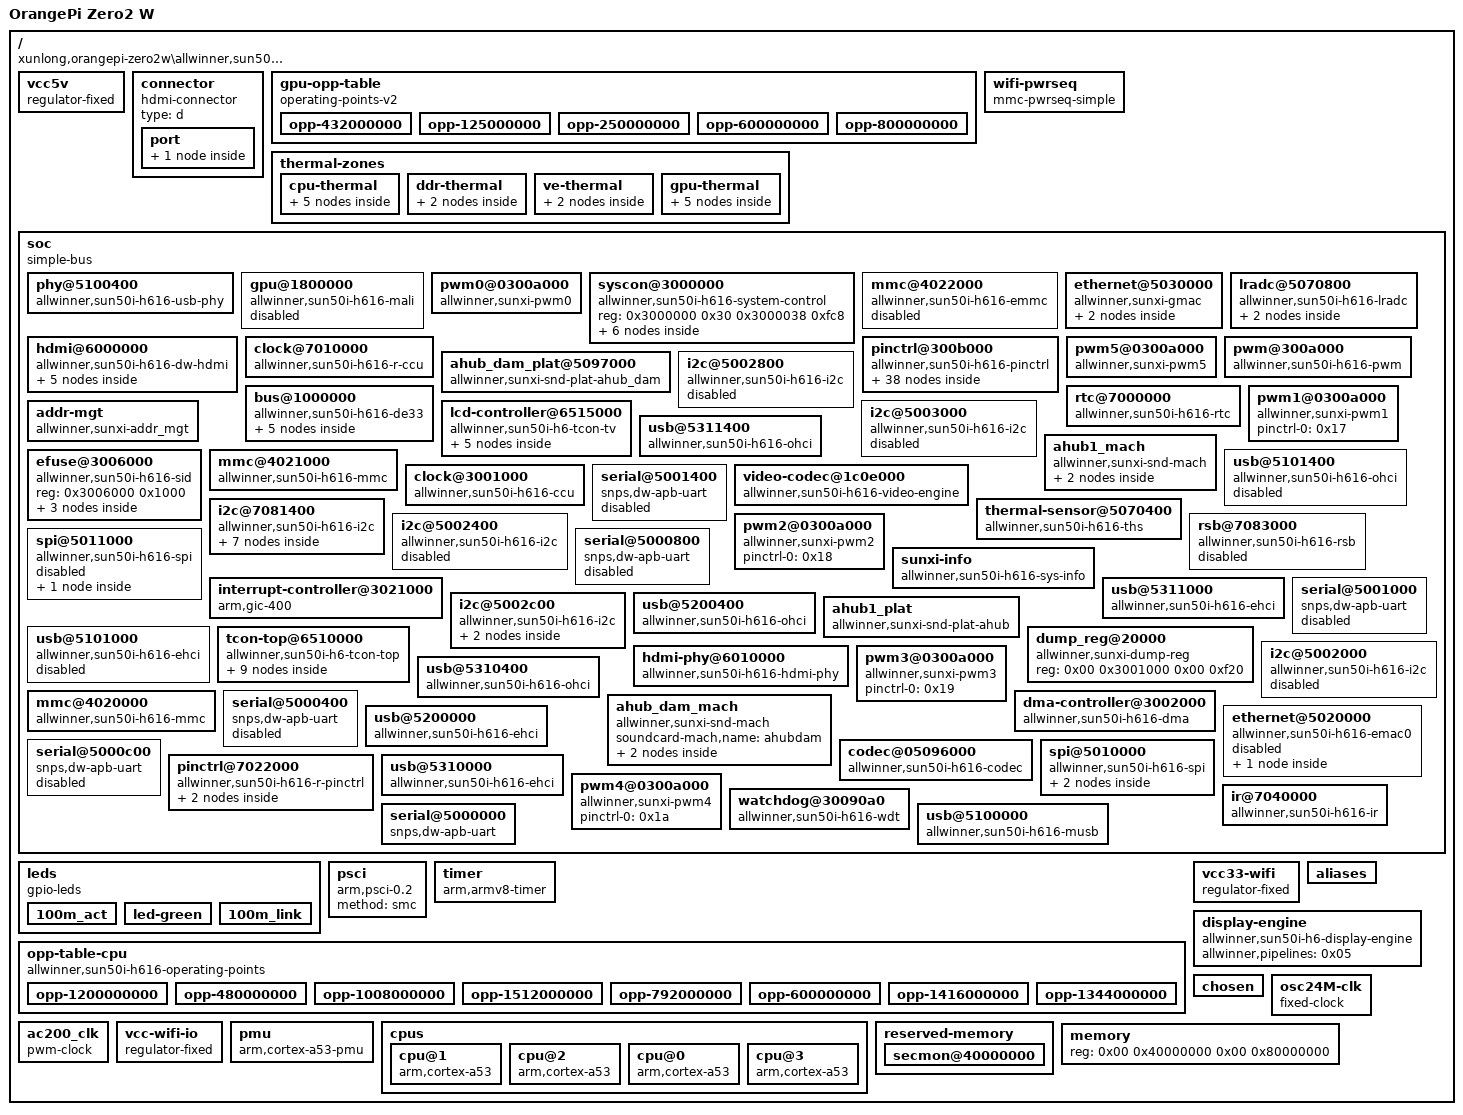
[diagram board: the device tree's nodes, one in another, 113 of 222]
/dts-v1/;

/ {
	#address-cells = <0x02>;
	model = "OrangePi Zero2 W";
	serial-number = "33802000c46ac590";
	#size-cells = <0x02>;
	interrupt-parent = <0x01>;
	compatible = "xunlong,orangepi-zero2w\allwinner,sun50i-h616\allwinner,sun50i-h618";

	vcc5v {
		regulator-max-microvolt = <0x4c4b40>;
		regulator-always-on;
		regulator-min-microvolt = <0x4c4b40>;
		regulator-name = "vcc-5v";
		compatible = "regulator-fixed";
		phandle = <0x52>;
	};

	connector {
		type = "d";
		compatible = "hdmi-connector";

		port {

			endpoint {
				remote-endpoint = <0x51>;
				phandle = <0x3f>;
			};
		};
	};

	gpu-opp-table {
		compatible = "operating-points-v2";
		phandle = <0xa2>;

		opp-432000000 {
			opp-microvolt = <0xc5c10>;
			opp-hz = <0x00 0x19bfcc00>;
		};

		opp-125000000 {
			opp-microvolt = <0xc5c10>;
			opp-hz = <0x00 0x7735940>;
		};

		opp-250000000 {
			opp-microvolt = <0xc5c10>;
			opp-hz = <0x00 0xee6b280>;
		};

		opp-600000000 {
			opp-microvolt = <0xea600>;
			opp-hz = <0x00 0x23c34600>;
		};

		opp-800000000 {
			opp-microvolt = <0x107ac0>;
			opp-hz = <0x00 0x2faf0800>;
		};
	};

	wifi-pwrseq {
		clock-names = "osc32k-out";
		clocks = <0x10 0x01>;
		reset-gpios = <0x1e 0x06 0x12 0x01>;
		compatible = "mmc-pwrseq-simple";
		post-power-on-delay-ms = <0xc8>;
		phandle = <0x22>;
	};

	thermal-zones {

		cpu-thermal {
			polling-delay = <0x00>;
			polling-delay-passive = <0x00>;
			thermal-sensors = <0x4c 0x02>;

			trips {

				cpu-crit {
					temperature = <0x186a0>;
					hysteresis = <0x00>;
					type = "critical";
				};

				cpu-alert {
					temperature = <0x14c08>;
					hysteresis = <0x7d0>;
					type = "passive";
					phandle = <0x4d>;
				};
			};

			cooling-maps {

				map0 {
					trip = <0x4d>;
					cooling-device = <0x06 0xffffffff 0xffffffff 0x07 0xffffffff 0xffffffff 0x08 0xffffffff 0xffffffff 0x09 0xffffffff 0xffffffff>;
				};
			};
		};

		ddr-thermal {
			polling-delay = <0x00>;
			polling-delay-passive = <0x00>;
			thermal-sensors = <0x4c 0x03>;

			trips {

				ddr-alert {
					temperature = <0x14c08>;
					hysteresis = <0x7d0>;
					type = "passive";
					phandle = <0xa1>;
				};
			};
		};

		ve-thermal {
			polling-delay = <0x00>;
			polling-delay-passive = <0x00>;
			thermal-sensors = <0x4c 0x01>;

			trips {

				ve-alert {
					temperature = <0x14c08>;
					hysteresis = <0x7d0>;
					type = "passive";
					phandle = <0xa0>;
				};
			};
		};

		gpu-thermal {
			polling-delay = <0x00>;
			polling-delay-passive = <0x00>;
			thermal-sensors = <0x4c 0x00>;

			trips {

				gpu-alert {
					temperature = <0x14c08>;
					hysteresis = <0x7d0>;
					type = "passive";
					phandle = <0x4e>;
				};

				gpu-crit {
					temperature = <0x186a0>;
					hysteresis = <0x00>;
					type = "critical";
				};
			};

			cooling-maps {

				map0 {
					trip = <0x4e>;
					cooling-device = <0x4f 0xffffffff 0xffffffff>;
				};
			};
		};
	};

	soc {
		#address-cells = <0x01>;
		#size-cells = <0x01>;
		compatible = "simple-bus";
		ranges = <0x00 0x00 0x00 0x40000000>;

		phy@5100400 {
			clock-names = "usb0_phy\0usb1_phy\0usb2_phy\0usb3_phy\0pmu2_clk";
			reg-names = "phy_ctrl\0pmu0\0pmu1\0pmu2\0pmu3";
			resets = <0x02 0x26 0x02 0x27 0x02 0x28 0x02 0x29>;
			clocks = <0x02 0x61 0x02 0x63 0x02 0x65 0x02 0x67 0x02 0x6e>;
			#phy-cells = <0x01>;
			compatible = "allwinner,sun50i-h616-usb-phy";
			status = "okay";
			reg = <0x5100400 0x24 0x5101800 0x14 0x5200800 0x14 0x5310800 0x14 0x5311800 0x14>;
			phandle = <0x3c>;
			reset-names = "usb0_reset\0usb1_reset\0usb2_reset\0usb3_reset";
		};

		gpu@1800000 {
			mali-supply = <0x0d>;
			clock-names = "core\0bus";
			resets = <0x02 0x03>;
			interrupts = <0x00 0x5f 0x04 0x00 0x60 0x04 0x00 0x61 0x04>;
			clocks = <0x02 0x23 0x02 0x24>;
			compatible = "allwinner,sun50i-h616-mali\0arm,mali-bifrost";
			status = "disabled";
			interrupt-names = "job\0mmu\0gpu";
			reg = <0x1800000 0x40000>;
			phandle = <0x4f>;
		};

		pwm0@0300a000 {
			compatible = "allwinner,sunxi-pwm0";
			phandle = <0x11>;
		};

		syscon@3000000 {
			#address-cells = <0x01>;
			#size-cells = <0x01>;
			compatible = "allwinner,sun50i-h616-system-control";
			ranges;
			reg = <0x3000000 0x30 0x3000038 0xfc8>;
			phandle = <0x39>;

			sram@1a00000 {
				#address-cells = <0x01>;
				#size-cells = <0x01>;
				compatible = "mmio-sram";
				ranges = <0x00 0x1a00000 0x200000>;
				reg = <0x1a00000 0x200000>;
				phandle = <0x59>;

				sram-section@0 {
					compatible = "allwinner,sun50i-h616-sram-c1";
					reg = <0x00 0x200000>;
					phandle = <0x0e>;
				};
			};

			sram@100000 {
				#address-cells = <0x01>;
				#size-cells = <0x01>;
				compatible = "mmio-sram";
				ranges = <0x00 0x100000 0x18000>;
				reg = <0x100000 0x18000>;
				phandle = <0x56>;

				scpi-sram@17c00 {
					compatible = "arm,scp-shmem";
					reg = <0x17c00 0x200>;
					phandle = <0x57>;
				};
			};

			sram@28000 {
				#address-cells = <0x01>;
				#size-cells = <0x01>;
				compatible = "mmio-sram";
				ranges = <0x00 0x28000 0x30000>;
				reg = <0x28000 0x30000>;
				phandle = <0x58>;

				sram-section@0 {
					compatible = "allwinner,sun50i-h616-sram-c\0allwinner,sun50i-a64-sram-c";
					reg = <0x00 0x1e000>;
					phandle = <0x0a>;
				};
			};
		};

		mmc@4022000 {
			mmc-ddr-3_3v;
			pinctrl-names = "default";
			#address-cells = <0x01>;
			pinctrl-0 = <0x23>;
			clock-names = "ahb\0mmc";
			cap-sd-highspeed;
			resets = <0x02 0x10>;
			cap-sdio-irq;
			interrupts = <0x00 0x25 0x04>;
			clocks = <0x02 0x41 0x02 0x3e>;
			#size-cells = <0x00>;
			compatible = "allwinner,sun50i-h616-emmc\0allwinner,sun50i-a100-emmc";
			status = "disabled";
			reg = <0x4022000 0x1000>;
			phandle = <0x6c>;
			max-frequency = <0x8f0d180>;
			cap-mmc-highspeed;
			reset-names = "ahb";
		};

		ethernet@5030000 {
			rx-delay = <0x1f>;
			gmac-power1;
			pinctrl-names = "default";
			phy-supply = <0x1d>;
			phy-mode = "rmii";
			phy-rst;
			tx-delay = <0x07>;
			pinctrl-0 = <0x3a>;
			clock-names = "bus-emac1\0emac-25m";
			reg-names = "gmac1_reg\0ephy_reg";
			local-mac-address = [02 00 c4 6a c5 90];
			resets = <0x02 0x1f>;
			interrupts = <0x00 0x0f 0x04>;
			clocks = <0x02 0x53 0x02 0x51>;
			gmac-power2;
			gmac-power0;
			compatible = "allwinner,sunxi-gmac";
			status = "okay";
			interrupt-names = "gmacirq";
			reg = <0x5030000 0x10000 0x3000034 0x04>;
			phandle = <0x82>;
			allwinner,tx-delay-ps = <0x2bc>;
			phy-handle = <0x3b>;
			reset-names = "stmmaceth";
			allwinner,rx-delay-ps = <0xc1c>;

			mdio {
				#address-cells = <0x01>;
				#size-cells = <0x00>;
				compatible = "ethernet-phy-ieee802.3-c22";
				phandle = <0x83>;

				ethernet-phy@1 {
					compatible = "ethernet-phy-ieee802.3-c22";
					reg = <0x01>;
					phandle = <0x3b>;
				};
			};
		};

		lradc@5070800 {
			vref-supply = <0x4b>;
			resets = <0x02 0x3b>;
			interrupts = <0x00 0x14 0x01>;
			clocks = <0x02 0x71>;
			compatible = "allwinner,sun50i-h616-lradc";
			status = "okay";
			reg = <0x5070800 0x400>;
			phandle = <0x9f>;

			button-500 {
				label = "KEY_1";
				channel = <0x00>;
				linux,code = <0x02>;
				voltage = <0x7a120>;
			};

			button-800 {
				label = "KEY_ENTER";
				channel = <0x00>;
				linux,code = <0x1c>;
				voltage = "\0\f5";
			};
		};

		hdmi@6000000 {
			reg-io-width = <0x01>;
			phy-names = "phy";
			clock-names = "iahb\0isfr\0tmds\0cec\0hdcp\0hdcp-bus";
			resets = <0x02 0x33 0x02 0x3a>;
			interrupts = <0x00 0x3f 0x04>;
			clocks = <0x02 0x75 0x02 0x73 0x02 0x72 0x02 0x74 0x02 0x7e 0x02 0x7f>;
			#sound-dai-cells = <0x00>;
			compatible = "allwinner,sun50i-h616-dw-hdmi\0allwinner,sun50i-h6-dw-hdmi";
			status = "okay";
			phys = <0x3d>;
			reg = <0x6000000 0x10000>;
			phandle = <0x28>;
			reset-names = "ctrl\0hdcp";

			ports {
				#address-cells = <0x01>;
				#size-cells = <0x00>;

				port@0 {
					reg = <0x00>;
					phandle = <0x8d>;

					endpoint {
						remote-endpoint = <0x3e>;
						phandle = <0x43>;
					};
				};

				port@1 {
					reg = <0x01>;
					phandle = <0x8e>;

					endpoint {
						remote-endpoint = <0x3f>;
						phandle = <0x51>;
					};
				};
			};
		};

		clock@7010000 {
			#reset-cells = <0x01>;
			clock-names = "hosc\0losc\0iosc\0pll-periph";
			clocks = <0x0f 0x10 0x00 0x10 0x02 0x02 0x04>;
			#clock-cells = <0x01>;
			compatible = "allwinner,sun50i-h616-r-ccu";
			reg = <0x7010000 0x210>;
			phandle = <0x47>;
		};

		pinctrl@300b000 {
			clock-names = "apb\0hosc\0losc";
			gpio-controller;
			interrupts = <0x00 0x33 0x04 0x00 0x34 0x04 0x00 0x35 0x04 0x00 0x2b 0x04 0x00 0x36 0x04 0x00 0x37 0x04 0x00 0x38 0x04 0x00 0x39 0x04>;
			clocks = <0x02 0x1a 0x0f 0x10 0x00>;
			compatible = "allwinner,sun50i-h616-pinctrl";
			#interrupt-cells = <0x03>;
			reg = <0x300b000 0x400>;
			phandle = <0x1e>;
			#gpio-cells = <0x03>;
			interrupt-controller;

			i2c4-ph-pins {
				function = "i2c4";
				pins = "PH6\0PH7";
				phandle = <0x34>;
			};

			pwm2-ph-pin {
				function = "pwm2";
				pins = "PH2";
				phandle = <0x62>;
			};

			pwm3-ph-pin {
				function = "pwm3";
				pins = "PH0";
				phandle = <0x63>;
			};

			pwm4-ph-pin {
				function = "pwm4";
				pins = "PH1";
				phandle = <0x64>;
			};

			spi1-cs0-pin {
				function = "spi1";
				pins = "PH5";
				phandle = <0x65>;
			};

			i2c1-pi-pins {
				function = "i2c1";
				pins = "PI7\0PI8";
				phandle = <0x2f>;
			};

			rmii-pins {
				function = "emac1";
				pins = "PA0\0PA1\0PA2\0PA3\0PA4\0PA5\0PA6\0PA7\0PA8\0PA9";
				drive-strength = <0x28>;
				phandle = <0x3a>;
			};

			pwm1-pi-pin {
				function = "pwm1";
				pins = "PI11";
				phandle = <0x17>;
			};

			pwm5-pin {
				function = "pwm5";
				pins = "PA12";
				phandle = <0x1b>;
			};

			mmc2-pins {
				function = "mmc2";
				pins = "PC0\0PC1\0PC5\0PC6\0PC8\0PC9\0PC10\0PC11\0PC13\0PC14\0PC15\0PC16";
				drive-strength = <0x1e>;
				phandle = <0x23>;
				bias-pull-up;
			};

			pwm2-pi-pin {
				function = "pwm2";
				pins = "PI12";
				phandle = <0x18>;
			};

			i2c1-ph-pins {
				function = "i2c1";
				pins = "PH0\0PH1";
				phandle = <0x5d>;
			};

			pwm3-pi-pin {
				function = "pwm3";
				pins = "PI13";
				phandle = <0x19>;
			};

			uart3-pi-pins {
				function = "uart3";
				pins = "PI9\0PI10";
				phandle = <0x2b>;
			};

			uart1-ph-pins {
				function = "uart1";
				pins = "PG6\0PG7";
				phandle = <0x66>;
			};

			pwm4-pi-pin {
				function = "pwm4";
				pins = "PI14";
				phandle = <0x1a>;
			};

			spi1-cs1-pin {
				function = "spi1";
				pins = "PH9";
				phandle = <0x38>;
			};

			ir-rx-pin {
				function = "ir_rx";
				pins = "PH10";
				phandle = <0x48>;
			};

			mmc1-pins {
				function = "mmc1";
				pins = "PG0\0PG1\0PG2\0PG3\0PG4\0PG5";
				drive-strength = <0x1e>;
				phandle = <0x1f>;
				bias-pull-up;
			};

			i2c3-ph-pins {
				function = "i2c3";
				pins = "PH4\0PH5";
				phandle = <0x5f>;
			};

			i2c3-pa-pins {
				function = "i2c3";
				pins = "PA10\0PA11";
				phandle = <0x31>;
				bias-pull-up;
			};

			rgmii-pins {
				function = "emac0";
				pins = "PI0\0PI1\0PI2\0PI3\0PI4\0PI5\0PI7\0PI8\0PI9\0PI10\0PI11\0PI12\0PI13\0PI14\0PI15\0PI16";
				drive-strength = <0x28>;
				phandle = <0x5c>;
			};

			mmc0-pins {
				function = "mmc0";
				pins = "PF0\0PF1\0PF2\0PF3\0PF4\0PF5";
				drive-strength = <0x1e>;
				phandle = <0x1c>;
				bias-pull-up;
			};

			spi0-cs0-pin {
				function = "spi0";
				pins = "PC3";
				phandle = <0x36>;
			};

			i2c0-pi-pins {
				function = "i2c0";
				pins = "PI5\0PI6";
				phandle = <0x2e>;
			};

			uart5-ph-pins {
				function = "uart5";
				pins = "PH2\0PH3";
				phandle = <0x2d>;
			};

			spi1-pins {
				function = "spi1";
				pins = "PH6\0PH7\0PH8";
				phandle = <0x37>;
			};

			i2s3-pins {
				function = "i2s3";
				pins = "PH5\0PH6\0PH7\0PH8\0PH9";
				phandle = <0x60>;
			};

			uart2-ph-rts-cts-pins {
				function = "uart2";
				pins = "PH7\0PH8";
				phandle = <0x69>;
			};

			i2c2-pi-pins {
				function = "i2c2";
				pins = "PI9\0PI10";
				phandle = <0x30>;
			};

			uart2-pi-pins {
				function = "uart2";
				pins = "PI5\0PI6";
				phandle = <0x2a>;
			};

			uart0-ph-pins {
				function = "uart0";
				pins = "PH0\0PH1";
				phandle = <0x29>;
			};

			spi0-pins {
				function = "spi0";
				pins = "PC0\0PC2\0PC4";
				phandle = <0x35>;
			};

			uart1-ph-rts-cts-pins {
				function = "uart1";
				pins = "PG8\0PG9";
				phandle = <0x67>;
			};

			i2c2-ph-pins {
				function = "i2c2";
				pins = "PH2\0PH3";
				phandle = <0x5e>;
			};

			uart4-pi-pins {
				function = "uart4";
				pins = "PI13\0PI14";
				phandle = <0x2c>;
			};

			uart2-ph-pins {
				function = "uart2";
				pins = "PH5\0PH6";
				phandle = <0x68>;
			};

			pwm1-ph-pin {
				function = "pwm1";
				pins = "PH3";
				phandle = <0x61>;
			};
		};

		pwm5@0300a000 {
			pinctrl-names = "default";
			clk_bypass_output = <0x01>;
			pinctrl-0 = <0x1b>;
			compatible = "allwinner,sunxi-pwm5";
			status = "okay";
			phandle = <0x16>;
		};

		pwm@300a000 {
			clock-names = "mod\0bus";
			resets = <0x02 0x0a>;
			clocks = <0x0f 0x02 0x2f>;
			pwm-number = <0x06>;
			#pwm-cells = <0x03>;
			compatible = "allwinner,sun50i-h616-pwm";
			status = "okay";
			reg = <0x300a000 0x400>;
			phandle = <0x53>;
			pwm-base = <0x00>;
			sunxi-pwms = <0x11 0x12 0x13 0x14 0x15 0x16>;
		};

		ahub_dam_plat@5097000 {
			clock-names = "clk_pll_audio\0clk_pll_audio_4x\0clk_audio_hub\0clk_bus_audio_hub";
			resets = <0x02 0x25>;
			clocks = <0x02 0x5b 0x02 0x5c 0x02 0x5e 0x02 0x5f>;
			#sound-dai-cells = <0x00>;
			compatible = "allwinner,sunxi-snd-plat-ahub_dam";
			status = "okay";
			reg = <0x5097000 0x1000>;
			phandle = <0x25>;
		};

		bus@1000000 {
			#address-cells = <0x01>;
			allwinner,sram = <0x0a 0x01>;
			#size-cells = <0x01>;
			compatible = "allwinner,sun50i-h616-de33\0allwinner,sun50i-a64-de2";
			ranges = <0x00 0x1000000 0x400000>;
			reg = <0x1000000 0x400000>;

			mixer@100000 {
				clock-names = "bus\0mod";
				resets = <0x0b 0x00>;
				clocks = <0x0b 0x00 0x0b 0x06>;
				compatible = "allwinner,sun50i-h616-de33-mixer-0";
				reg = <0x100000 0x100000 0x8100 0x40 0x280000 0x20000>;
				phandle = <0x05>;

				ports {
					#address-cells = <0x01>;
					#size-cells = <0x00>;

					port@1 {
						reg = <0x01>;
						phandle = <0x55>;

						endpoint {
							remote-endpoint = <0x0c>;
							phandle = <0x40>;
						};
					};
				};
			};

			clock@8000 {
				#reset-cells = <0x01>;
				clock-names = "mod\0bus";
				resets = <0x02 0x01>;
				clocks = <0x02 0x1d 0x02 0x1e>;
				#clock-cells = <0x01>;
				compatible = "allwinner,sun50i-h616-de33-clk";
				reg = <0x8000 0x100>;
				phandle = <0x0b>;
			};
		};

		i2c@5002800 {
			pinctrl-names = "default";
			#address-cells = <0x01>;
			pinctrl-0 = <0x30>;
			resets = <0x02 0x19>;
			interrupts = <0x00 0x08 0x04>;
			clocks = <0x02 0x4a>;
			#size-cells = <0x00>;
			compatible = "allwinner,sun50i-h616-i2c\0allwinner,sun8i-v536-i2c\0allwinner,sun6i-a31-i2c";
			status = "disabled";
			reg = <0x5002800 0x400>;
			phandle = <0x79>;
		};

		rtc@7000000 {
			clock-names = "bus\0hosc\0pll-32k";
			interrupts = <0x00 0x68 0x04>;
			clocks = <0x47 0x0e 0x0f 0x02 0x80>;
			#clock-cells = <0x01>;
			compatible = "allwinner,sun50i-h616-rtc";
			reg = <0x7000000 0x400>;
			phandle = <0x10>;
		};

		pwm1@0300a000 {
			pinctrl-names = "default";
			pinctrl-0 = <0x17>;
			compatible = "allwinner,sunxi-pwm1";
			phandle = <0x12>;
		};

		addr-mgt {
			compatible = "allwinner,sunxi-addr_mgt";
			status = "okay";
			type_addr_eth = <0x02>;
			type_addr_wifi = <0x02>;
			phandle = <0x9e>;
			type_addr_bt = <0x02>;
		};

		lcd-controller@6515000 {
			clock-names = "ahb\0tcon-ch1";
			resets = <0x02 0x36>;
			interrupts = <0x00 0x42 0x04>;
			clocks = <0x02 0x79 0x44 0x00>;
			compatible = "allwinner,sun50i-h6-tcon-tv\0allwinner,sun8i-r40-tcon-tv";
			reg = <0x6515000 0x1000>;
			phandle = <0x93>;
			reset-names = "lcd";

			ports {
				#address-cells = <0x01>;
				#size-cells = <0x00>;

				port@0 {
					reg = <0x00>;
					phandle = <0x94>;

					endpoint {
						remote-endpoint = <0x45>;
						phandle = <0x41>;
					};
				};

				port@1 {
					#address-cells = <0x01>;
					#size-cells = <0x00>;
					reg = <0x01>;
					phandle = <0x95>;

					endpoint@1 {
						remote-endpoint = <0x46>;
						reg = <0x01>;
						phandle = <0x42>;
					};
				};
			};
		};

		i2c@5003000 {
			pinctrl-names = "default";
			#address-cells = <0x01>;
			pinctrl-0 = <0x34>;
			resets = <0x02 0x1b>;
			interrupts = <0x00 0x0a 0x04>;
			clocks = <0x02 0x4c>;
			#size-cells = <0x00>;
			compatible = "allwinner,sun50i-h616-i2c\0allwinner,sun8i-v536-i2c\0allwinner,sun6i-a31-i2c";
			status = "disabled";
			reg = <0x5003000 0x400>;
			phandle = <0x7d>;
		};

		usb@5311400 {
			phy-names = "usb";
			resets = <0x02 0x2d 0x02 0x28>;
			interrupts = <0x00 0x21 0x04>;
			clocks = <0x02 0x6b 0x02 0x66 0x02 0x65>;
			compatible = "allwinner,sun50i-h616-ohci\0generic-ohci";
			status = "okay";
			phys = <0x3c 0x03>;
			reg = <0x5311400 0x100>;
			phandle = <0x8c>;
		};

		ahub1_mach {
			soundcard-mach,slot-num = <0x02>;
			soundcard-mach,slot-width = <0x20>;
			compatible = "allwinner,sunxi-snd-mach";
			status = "okay";
			soundcard-mach,frame-master = <0x26>;
			phandle = <0x6f>;
			soundcard-mach,name = "ahubhdmi";
			soundcard-mach,format = "i2s";
			soundcard-mach,bitclock-master = <0x26>;

			soundcard-mach,codec {
				phandle = <0x70>;
				sound-dai = <0x28>;
			};

			soundcard-mach,cpu {
				soundcard-mach,mclk-fs = <0x00>;
				soundcard-mach,pll-fs = <0x04>;
				phandle = <0x26>;
				sound-dai = <0x27>;
			};
		};

		efuse@3006000 {
			#address-cells = <0x01>;
			#size-cells = <0x01>;
			compatible = "allwinner,sun50i-h616-sid";
			reg = <0x3006000 0x1000>;
			phandle = <0x5a>;

			thermal-sensor-calibration@14 {
				reg = <0x14 0x08>;
				phandle = <0x4a>;
			};

			cpu-speed-grade@00 {
				reg = <0x00 0x02>;
				phandle = <0x50>;
			};

			ephy-calibration@2c {
				reg = <0x2c 0x02>;
				phandle = <0x33>;
			};
		};

		mmc@4021000 {
			mmc-ddr-3_3v;
			pinctrl-names = "default";
			#address-cells = <0x01>;
			pinctrl-0 = <0x1f>;
			clock-names = "ahb\0mmc";
			cap-sd-highspeed;
			vqmmc-supply = <0x21>;
			bus-width = <0x04>;
			non-removable;
			resets = <0x02 0x0f>;
			cap-sdio-irq;
			interrupts = <0x00 0x24 0x04>;
			clocks = <0x02 0x40 0x02 0x3d>;
			#size-cells = <0x00>;
			vmmc-supply = <0x20>;
			mmc-ddr-1_8v;
			compatible = "allwinner,sun50i-h616-mmc\0allwinner,sun50i-a100-mmc";
			status = "okay";
			mmc-pwrseq = <0x22>;
			reg = <0x4021000 0x1000>;
			phandle = <0x6b>;
			max-frequency = <0x8f0d180>;
			cap-mmc-highspeed;
			reset-names = "ahb";
		};

		usb@5101400 {
			phy-names = "usb";
			resets = <0x02 0x2a 0x02 0x28>;
			interrupts = <0x00 0x1b 0x04>;
			clocks = <0x02 0x68 0x02 0x60 0x02 0x65>;
			compatible = "allwinner,sun50i-h616-ohci\0generic-ohci";
			status = "disabled";
			phys = <0x3c 0x00>;
			reg = <0x5101400 0x100>;
			phandle = <0x86>;
		};

		clock@3001000 {
			#reset-cells = <0x01>;
			clock-names = "hosc\0losc\0iosc";
			clocks = <0x0f 0x10 0x00 0x10 0x02>;
			#clock-cells = <0x01>;
			compatible = "allwinner,sun50i-h616-ccu";
			reg = <0x3001000 0x1000>;
			phandle = <0x02>;
		};

		serial@5001400 {
			reg-io-width = <0x04>;
			pinctrl-names = "default";
			pinctrl-0 = <0x2d>;
			resets = <0x02 0x16>;
			interrupts = <0x00 0x05 0x04>;
			clocks = <0x02 0x47>;
			compatible = "snps,dw-apb-uart";
			status = "disabled";
			reg = <0x5001400 0x400>;
			phandle = <0x76>;
			reg-shift = <0x02>;
		};

		video-codec@1c0e000 {
			clock-names = "ahb\0mod\0ram";
			allwinner,sram = <0x0e 0x01>;
			resets = <0x02 0x05>;
			interrupts = <0x00 0x5d 0x04>;
			clocks = <0x02 0x29 0x02 0x28 0x02 0x33>;
			compatible = "allwinner,sun50i-h616-video-engine";
			reg = <0x1c0e000 0x2000>;
		};

		thermal-sensor@5070400 {
			nvmem-cells = <0x4a>;
			clock-names = "bus";
			resets = <0x02 0x21>;
			interrupts = <0x00 0x13 0x04>;
			clocks = <0x02 0x56>;
			#thermal-sensor-cells = <0x01>;
			compatible = "allwinner,sun50i-h616-ths";
			nvmem-cell-names = "calibration";
			reg = <0x5070400 0x400>;
			phandle = <0x4c>;
		};

		i2c@7081400 {
			#address-cells = <0x01>;
			resets = <0x47 0x04>;
			interrupts = <0x00 0x69 0x04>;
			clocks = <0x47 0x08>;
			#size-cells = <0x00>;
			compatible = "allwinner,sun50i-h616-i2c\0allwinner,sun8i-v536-i2c\0allwinner,sun6i-a31-i2c";
			status = "okay";
			reg = <0x7081400 0x400>;
			phandle = <0x99>;

			pmic@36 {
				wakeup-source;
				interrupts = <0x02 0x09 0x08>;
				interrupt-parent = <0x1e>;
				compatible = "x-powers,axp313a";
				#interrupt-cells = <0x01>;
				reg = <0x36>;
				phandle = <0x9a>;
				interrupt-controller;

				regulators {

					dcdc3 {
						regulator-max-microvolt = <0x10c8e0>;
						regulator-step-delay-us = <0x19>;
						regulator-always-on;
						regulator-min-microvolt = <0x10c8e0>;
						regulator-name = "axp313a-dcdc3";
						regulator-final-delay-us = <0x32>;
						phandle = <0x9b>;
					};

					dcdc1 {
						regulator-max-microvolt = <0x10c8e0>;
						regulator-step-delay-us = <0x19>;
						regulator-always-on;
						regulator-min-microvolt = <0x7a120>;
						regulator-name = "axp313a-dcdc1";
						regulator-final-delay-us = <0x32>;
						phandle = <0x0d>;
					};

					ldo2 {
						regulator-max-microvolt = <0x325aa0>;
						regulator-step-delay-us = <0x19>;
						regulator-always-on;
						regulator-min-microvolt = <0x325aa0>;
						regulator-name = "axp313a-dldo1";
						regulator-final-delay-us = <0x32>;
						phandle = <0x1d>;
					};

					dcdc2 {
						regulator-max-microvolt = <0x124f80>;
						regulator-step-delay-us = <0x19>;
						regulator-always-on;
						regulator-min-microvolt = <0x7a120>;
						regulator-name = "axp313a-dcdc2";
						regulator-ramp-delay = <0xc8>;
						regulator-final-delay-us = <0x32>;
						phandle = <0x04>;
					};

					ldo1 {
						regulator-max-microvolt = <0x1b7740>;
						regulator-step-delay-us = <0x19>;
						regulator-always-on;
						regulator-min-microvolt = <0x1b7740>;
						regulator-name = "axp313a-aldo1";
						regulator-final-delay-us = <0x32>;
						phandle = <0x4b>;
					};
				};
			};
		};

		i2c@5002400 {
			pinctrl-names = "default";
			#address-cells = <0x01>;
			pinctrl-0 = <0x2f>;
			resets = <0x02 0x18>;
			interrupts = <0x00 0x07 0x04>;
			clocks = <0x02 0x49>;
			#size-cells = <0x00>;
			compatible = "allwinner,sun50i-h616-i2c\0allwinner,sun8i-v536-i2c\0allwinner,sun6i-a31-i2c";
			status = "disabled";
			reg = <0x5002400 0x400>;
			phandle = <0x78>;
		};

		pwm2@0300a000 {
			pinctrl-names = "default";
			pinctrl-0 = <0x18>;
			compatible = "allwinner,sunxi-pwm2";
			phandle = <0x13>;
		};

		rsb@7083000 {
			pinctrl-names = "default";
			#address-cells = <0x01>;
			pinctrl-0 = <0x49>;
			resets = <0x47 0x07>;
			interrupts = <0x00 0x6d 0x04>;
			clocks = <0x47 0x0d>;
			#size-cells = <0x00>;
			clock-frequency = <0x2dc6c0>;
			compatible = "allwinner,sun50i-h616-rsb\0allwinner,sun8i-a23-rsb";
			status = "disabled";
			reg = <0x7083000 0x400>;
			phandle = <0x9c>;
		};

		sunxi-info {
			compatible = "allwinner,sun50i-h616-sys-info";
			status = "okay";
		};

		spi@5011000 {
			pinctrl-names = "default";
			#address-cells = <0x01>;
			pinctrl-0 = <0x37 0x38>;
			clock-names = "ahb\0mod";
			resets = <0x02 0x1d>;
			interrupts = <0x00 0x0d 0x04>;
			clocks = <0x02 0x50 0x02 0x4e>;
			#size-cells = <0x00>;
			dma-names = "rx\0tx";
			compatible = "allwinner,sun50i-h616-spi\0allwinner,sun8i-h3-spi";
			status = "disabled";
			reg = <0x5011000 0x1000>;
			phandle = <0x7f>;
			dmas = <0x24 0x17 0x24 0x17>;

			spidev@1 {
				spi-max-frequency = <0xf4240>;
				compatible = "rohm,dh2228fv";
				status = "disabled";
				reg = <0x01>;
			};
		};

		serial@5000800 {
			reg-io-width = <0x04>;
			pinctrl-names = "default";
			pinctrl-0 = <0x2a>;
			resets = <0x02 0x13>;
			interrupts = <0x00 0x02 0x04>;
			clocks = <0x02 0x44>;
			compatible = "snps,dw-apb-uart";
			status = "disabled";
			reg = <0x5000800 0x400>;
			phandle = <0x73>;
			reg-shift = <0x02>;
		};

		interrupt-controller@3021000 {
			interrupts = <0x01 0x09 0xf04>;
			compatible = "arm,gic-400";
			#interrupt-cells = <0x03>;
			reg = <0x3021000 0x1000 0x3022000 0x2000 0x3024000 0x2000 0x3026000 0x2000>;
			phandle = <0x01>;
			interrupt-controller;
		};

		usb@5311000 {
			phy-names = "usb";
			resets = <0x02 0x2d 0x02 0x31 0x02 0x28>;
			interrupts = <0x00 0x20 0x04>;
			clocks = <0x02 0x6b 0x02 0x6f 0x02 0x66 0x02 0x65>;
			compatible = "allwinner,sun50i-h616-ehci\0generic-ehci";
			status = "okay";
			phys = <0x3c 0x03>;
			reg = <0x5311000 0x100>;
			phandle = <0x8b>;
		};

		i2c@5002c00 {
			pinctrl-names = "default";
			#address-cells = <0x01>;
			pinctrl-0 = <0x31>;
			resets = <0x02 0x1a>;
			interrupts = <0x00 0x09 0x04>;
			clocks = <0x02 0x4b>;
			#size-cells = <0x00>;
			compatible = "allwinner,sun50i-h616-i2c\0allwinner,sun8i-v536-i2c\0allwinner,sun6i-a31-i2c";
			status = "okay";
			reg = <0x5002c00 0x400>;
			phandle = <0x7a>;

			mfd@10 {
				nvmem-cells = <0x33>;
				clocks = <0x32>;
				compatible = "x-powers,ac200";
				nvmem-cell-names = "calibration";
				reg = <0x10>;
				phandle = <0x7b>;

				phy {
					compatible = "x-powers,ac200-ephy";
					status = "okay";
					phandle = <0x7c>;
				};
			};
		};

		usb@5200400 {
			phy-names = "usb";
			resets = <0x02 0x2b 0x02 0x28>;
			interrupts = <0x00 0x1d 0x04>;
			clocks = <0x02 0x69 0x02 0x62 0x02 0x65>;
			compatible = "allwinner,sun50i-h616-ohci\0generic-ohci";
			status = "okay";
			phys = <0x3c 0x01>;
			reg = <0x5200400 0x100>;
			phandle = <0x88>;
		};

		ahub1_plat {
			capture_cma = <0x80>;
			rx_fifo_size = <0x80>;
			rx_pin = <0x00>;
			dma-names = "tx\0rx";
			#sound-dai-cells = <0x00>;
			compatible = "allwinner,sunxi-snd-plat-ahub";
			status = "okay";
			tdm_num = <0x01>;
			phandle = <0x27>;
			dmas = <0x24 0x04 0x24 0x04>;
			playback_cma = <0x80>;
			tx_fifo_size = <0x80>;
			tx_pin = <0x00>;
			apb_num = <0x01>;
		};

		usb@5101000 {
			phy-names = "usb";
			resets = <0x02 0x2a 0x02 0x2e 0x02 0x28>;
			interrupts = <0x00 0x1a 0x04>;
			clocks = <0x02 0x68 0x02 0x6c 0x02 0x60 0x02 0x65>;
			compatible = "allwinner,sun50i-h616-ehci\0generic-ehci";
			status = "disabled";
			phys = <0x3c 0x00>;
			reg = <0x5101000 0x100>;
			phandle = <0x85>;
		};

		tcon-top@6510000 {
			clock-output-names = "tcon-top-tv0";
			clock-names = "bus\0tcon-tv0";
			resets = <0x02 0x35>;
			clocks = <0x02 0x76 0x02 0x77>;
			#clock-cells = <0x01>;
			compatible = "allwinner,sun50i-h6-tcon-top";
			reg = <0x6510000 0x1000>;
			phandle = <0x44>;

			ports {
				#address-cells = <0x01>;
				#size-cells = <0x00>;

				port@0 {
					#address-cells = <0x01>;
					#size-cells = <0x00>;
					reg = <0x00>;
					phandle = <0x8f>;

					endpoint@0 {
						remote-endpoint = <0x40>;
						reg = <0x00>;
						phandle = <0x0c>;
					};
				};

				port@5 {
					reg = <0x05>;
					phandle = <0x92>;

					endpoint {
						remote-endpoint = <0x43>;
						phandle = <0x3e>;
					};
				};

				port@1 {
					#address-cells = <0x01>;
					#size-cells = <0x00>;
					reg = <0x01>;
					phandle = <0x90>;

					endpoint@2 {
						remote-endpoint = <0x41>;
						reg = <0x02>;
						phandle = <0x45>;
					};
				};

				port@4 {
					#address-cells = <0x01>;
					#size-cells = <0x00>;
					reg = <0x04>;
					phandle = <0x91>;

					endpoint@0 {
						remote-endpoint = <0x42>;
						reg = <0x00>;
						phandle = <0x46>;
					};
				};
			};
		};

		serial@5001000 {
			reg-io-width = <0x04>;
			pinctrl-names = "default";
			pinctrl-0 = <0x2c>;
			resets = <0x02 0x15>;
			interrupts = <0x00 0x04 0x04>;
			clocks = <0x02 0x46>;
			compatible = "snps,dw-apb-uart";
			status = "disabled";
			reg = <0x5001000 0x400>;
			phandle = <0x75>;
			reg-shift = <0x02>;
		};

		dump_reg@20000 {
			compatible = "allwinner,sunxi-dump-reg";
			status = "okay";
			reg = <0x00 0x3001000 0x00 0xf20>;
			phandle = <0x9d>;
		};

		hdmi-phy@6010000 {
			clock-names = "bus\0mod";
			resets = <0x02 0x34>;
			clocks = <0x02 0x75 0x02 0x73>;
			#phy-cells = <0x00>;
			compatible = "allwinner,sun50i-h616-hdmi-phy";
			reg = <0x6010000 0x10000>;
			phandle = <0x3d>;
			reset-names = "phy";
		};

		i2c@5002000 {
			pinctrl-names = "default";
			#address-cells = <0x01>;
			pinctrl-0 = <0x2e>;
			resets = <0x02 0x17>;
			interrupts = <0x00 0x06 0x04>;
			clocks = <0x02 0x48>;
			#size-cells = <0x00>;
			compatible = "allwinner,sun50i-h616-i2c\0allwinner,sun8i-v536-i2c\0allwinner,sun6i-a31-i2c";
			status = "disabled";
			reg = <0x5002000 0x400>;
			phandle = <0x77>;
		};

		pwm3@0300a000 {
			pinctrl-names = "default";
			pinctrl-0 = <0x19>;
			compatible = "allwinner,sunxi-pwm3";
			phandle = <0x14>;
		};

		usb@5310400 {
			phy-names = "usb";
			resets = <0x02 0x2c>;
			interrupts = <0x00 0x1f 0x04>;
			clocks = <0x02 0x6a 0x02 0x64>;
			compatible = "allwinner,sun50i-h616-ohci\0generic-ohci";
			status = "okay";
			phys = <0x3c 0x02>;
			reg = <0x5310400 0x100>;
			phandle = <0x8a>;
		};

		mmc@4020000 {
			mmc-ddr-3_3v;
			pinctrl-names = "default";
			#address-cells = <0x01>;
			pinctrl-0 = <0x1c>;
			clock-names = "ahb\0mmc";
			cap-sd-highspeed;
			bus-width = <0x04>;
			resets = <0x02 0x0e>;
			cap-sdio-irq;
			interrupts = <0x00 0x23 0x04>;
			clocks = <0x02 0x3f 0x02 0x3c>;
			#size-cells = <0x00>;
			vmmc-supply = <0x1d>;
			compatible = "allwinner,sun50i-h616-mmc\0allwinner,sun50i-a100-mmc";
			status = "okay";
			reg = <0x4020000 0x1000>;
			phandle = <0x6a>;
			max-frequency = <0x2faf080>;
			cap-mmc-highspeed;
			reset-names = "ahb";
			cd-gpios = <0x1e 0x05 0x06 0x01>;
		};

		serial@5000400 {
			reg-io-width = <0x04>;
			resets = <0x02 0x12>;
			interrupts = <0x00 0x01 0x04>;
			clocks = <0x02 0x43>;
			compatible = "snps,dw-apb-uart";
			status = "disabled";
			reg = <0x5000400 0x400>;
			phandle = <0x72>;
			reg-shift = <0x02>;
		};

		dma-controller@3002000 {
			clock-names = "bus\0mbus";
			resets = <0x02 0x06>;
			interrupts = <0x00 0x2a 0x04>;
			clocks = <0x02 0x2a 0x02 0x32>;
			dma-requests = <0x31>;
			compatible = "allwinner,sun50i-h616-dma";
			reg = <0x3002000 0x1000>;
			phandle = <0x24>;
			dma-channels = <0x10>;
			#dma-cells = <0x01>;
		};

		ahub_dam_mach {
			compatible = "allwinner,sunxi-snd-mach";
			status = "okay";
			phandle = <0x6e>;
			soundcard-mach,name = "ahubdam";

			soundcard-mach,codec {
			};

			soundcard-mach,cpu {
				sound-dai = <0x25>;
			};
		};

		usb@5200000 {
			phy-names = "usb";
			resets = <0x02 0x2b 0x02 0x2f 0x02 0x28>;
			interrupts = <0x00 0x1c 0x04>;
			clocks = <0x02 0x69 0x02 0x6d 0x02 0x62 0x02 0x65>;
			compatible = "allwinner,sun50i-h616-ehci\0generic-ehci";
			status = "okay";
			phys = <0x3c 0x01>;
			reg = <0x5200000 0x100>;
			phandle = <0x87>;
		};

		ethernet@5020000 {
			syscon = <0x39>;
			clock-names = "stmmaceth";
			resets = <0x02 0x1e>;
			interrupts = <0x00 0x0e 0x04>;
			clocks = <0x02 0x52>;
			compatible = "allwinner,sun50i-h616-emac0\0allwinner,sun50i-a64-emac";
			status = "disabled";
			interrupt-names = "macirq";
			reg = <0x5020000 0x10000>;
			phandle = <0x80>;
			reset-names = "stmmaceth";

			mdio {
				#address-cells = <0x01>;
				#size-cells = <0x00>;
				compatible = "snps,dwmac-mdio";
				phandle = <0x81>;
			};
		};

		codec@05096000 {
			clock-names = "apb\0audio-codec-1x\0audio-codec-4x";
			resets = <0x02 0x24>;
			interrupts = <0x00 0x3a 0x04>;
			clocks = <0x02 0x5d 0x02 0x5b 0x02 0x5c>;
			dma-names = "tx";
			#sound-dai-cells = <0x00>;
			compatible = "allwinner,sun50i-h616-codec";
			status = "okay";
			reg = <0x5096000 0x31c>;
			phandle = <0x6d>;
			dmas = <0x24 0x06>;
			allwinner,audio-routing = "Line Out\0LINEOUT";
		};

		serial@5000c00 {
			reg-io-width = <0x04>;
			pinctrl-names = "default";
			pinctrl-0 = <0x2b>;
			resets = <0x02 0x14>;
			interrupts = <0x00 0x03 0x04>;
			clocks = <0x02 0x45>;
			compatible = "snps,dw-apb-uart";
			status = "disabled";
			reg = <0x5000c00 0x400>;
			phandle = <0x74>;
			reg-shift = <0x02>;
		};

		spi@5010000 {
			pinctrl-names = "default";
			#address-cells = <0x01>;
			pinctrl-0 = <0x35 0x36>;
			clock-names = "ahb\0mod";
			resets = <0x02 0x1c>;
			interrupts = <0x00 0x0c 0x04>;
			clocks = <0x02 0x4f 0x02 0x4d>;
			#size-cells = <0x00>;
			dma-names = "rx\0tx";
			compatible = "allwinner,sun50i-h616-spi\0allwinner,sun8i-h3-spi";
			status = "okay";
			reg = <0x5010000 0x1000>;
			phandle = <0x7e>;
			dmas = <0x24 0x16 0x24 0x16>;

			spidev@0 {
				spi-max-frequency = <0xf4240>;
				compatible = "rohm,dh2228fv";
				status = "disabled";
				reg = <0x00>;
			};

			flash@0 {
				#address-cells = <0x01>;
				#size-cells = <0x01>;
				spi-max-frequency = <0x2625a00>;
				compatible = "jedec,spi-nor";
				status = "okay";
				reg = <0x00>;
			};
		};

		pinctrl@7022000 {
			clock-names = "apb\0hosc\0losc";
			gpio-controller;
			interrupts = <0x00 0x2b 0x04>;
			clocks = <0x47 0x02 0x0f 0x10 0x00>;
			compatible = "allwinner,sun50i-h616-r-pinctrl";
			#interrupt-cells = <0x03>;
			reg = <0x7022000 0x400>;
			phandle = <0x96>;
			#gpio-cells = <0x03>;
			interrupt-controller;

			r-rsb-pins {
				function = "s_rsb";
				pins = "PL0\0PL1";
				phandle = <0x49>;
			};

			r-i2c-pins {
				function = "s_i2c";
				pins = "PL0\0PL1";
				phandle = <0x97>;
			};
		};

		usb@5310000 {
			phy-names = "usb";
			resets = <0x02 0x2c 0x02 0x30>;
			interrupts = <0x00 0x1e 0x04>;
			clocks = <0x02 0x6a 0x02 0x6e 0x02 0x64>;
			compatible = "allwinner,sun50i-h616-ehci\0generic-ehci";
			status = "okay";
			phys = <0x3c 0x02>;
			reg = <0x5310000 0x100>;
			phandle = <0x89>;
		};

		pwm4@0300a000 {
			pinctrl-names = "default";
			pinctrl-0 = <0x1a>;
			compatible = "allwinner,sunxi-pwm4";
			phandle = <0x15>;
		};

		ir@7040000 {
			pinctrl-names = "default";
			pinctrl-0 = <0x48>;
			clock-names = "apb\0ir";
			resets = <0x47 0x05>;
			interrupts = <0x00 0x6a 0x04>;
			clocks = <0x47 0x09 0x47 0x0b>;
			compatible = "allwinner,sun50i-h616-ir\0allwinner,sun6i-a31-ir";
			status = "okay";
			reg = <0x7040000 0x400>;
			phandle = <0x98>;
		};

		watchdog@30090a0 {
			interrupts = <0x00 0x32 0x04>;
			clocks = <0x0f>;
			compatible = "allwinner,sun50i-h616-wdt\0allwinner,sun6i-a31-wdt";
			status = "okay";
			reg = <0x30090a0 0x20>;
			phandle = <0x5b>;
		};

		usb@5100000 {
			phy-names = "usb";
			resets = <0x02 0x32>;
			interrupts = <0x00 0x19 0x04>;
			clocks = <0x02 0x70>;
			extcon = <0x3c 0x00>;
			compatible = "allwinner,sun50i-h616-musb\0allwinner,sun8i-h3-musb";
			status = "okay";
			interrupt-names = "mc";
			phys = <0x3c 0x00>;
			reg = <0x5100000 0x400>;
			phandle = <0x84>;
			dr_mode = "peripheral";
		};

		serial@5000000 {
			reg-io-width = <0x04>;
			pinctrl-names = "default";
			pinctrl-0 = <0x29>;
			resets = <0x02 0x11>;
			interrupts = <0x00 0x00 0x04>;
			clocks = <0x02 0x42>;
			compatible = "snps,dw-apb-uart";
			status = "okay";
			reg = <0x5000000 0x400>;
			phandle = <0x71>;
			reg-shift = <0x02>;
		};
	};

	leds {
		compatible = "gpio-leds";
		phandle = <0xa3>;

		100m_act {
			label = "100m_act";
			default-state = "off";
			gpios = <0x1e 0x02 0x10 0x00>;
		};

		led-green {
			linux,default-trigger = "heartbeat";
			label = "green_led";
			gpios = <0x1e 0x02 0x0d 0x00>;
		};

		100m_link {
			label = "100m_link";
			default-state = "off";
			gpios = <0x1e 0x02 0x0f 0x00>;
		};
	};

	psci {
		method = "smc";
		compatible = "arm,psci-0.2";
	};

	timer {
		arm,no-tick-in-suspend;
		interrupts = <0x01 0x0d 0xf04 0x01 0x0e 0xf04 0x01 0x0b 0xf04 0x01 0x0a 0xf04>;
		compatible = "arm,armv8-timer";
	};

	opp-table-cpu {
		nvmem-cells = <0x50>;
		opp-shared;
		compatible = "allwinner,sun50i-h616-operating-points";
		phandle = <0x03>;

		opp-1200000000 {
			opp-microvolt-speed1 = <0x10c8e0 0x10c8e0 0x10c8e0>;
			opp-hz = <0x00 0x47868c00>;
			opp-microvolt-speed2 = <0x10c8e0 0x10c8e0 0x10c8e0>;
			opp-microvolt-speed0 = <0xea600 0xea600 0x10c8e0>;
			clock-latency-ns = <0x3b9b0>;
		};

		opp-480000000 {
			opp-microvolt-speed1 = <0xdbba0 0xdbba0 0x10c8e0>;
			opp-hz = <0x00 0x1c9c3800>;
			opp-microvolt-speed2 = <0xdbba0 0xdbba0 0x10c8e0>;
			opp-microvolt-speed0 = <0xdbba0 0xdbba0 0x10c8e0>;
			clock-latency-ns = <0x3b9b0>;
		};

		opp-1008000000 {
			opp-microvolt-speed1 = <0xf9060 0xf9060 0x10c8e0>;
			opp-hz = <0x00 0x3c14dc00>;
			opp-microvolt-speed2 = <0xf9060 0xf9060 0x10c8e0>;
			opp-microvolt-speed0 = <0xdbba0 0xdbba0 0x10c8e0>;
			clock-latency-ns = <0x3b9b0>;
		};

		opp-1512000000 {
			opp-microvolt-speed1 = <0x10c8e0 0x10c8e0 0x10c8e0>;
			opp-hz = <0x00 0x5a1f4a00>;
			opp-microvolt-speed2 = <0x10c8e0 0x10c8e0 0x10c8e0>;
			opp-microvolt-speed0 = <0x10c8e0 0x10c8e0 0x10c8e0>;
			clock-latency-ns = <0x3b9b0>;
		};

		opp-792000000 {
			opp-microvolt-speed1 = <0xe57e0 0xe57e0 0x10c8e0>;
			opp-hz = <0x00 0x2f34f600>;
			opp-microvolt-speed2 = <0xe57e0 0xe57e0 0x10c8e0>;
			opp-microvolt-speed0 = <0xdbba0 0xdbba0 0x10c8e0>;
			clock-latency-ns = <0x3b9b0>;
		};

		opp-600000000 {
			opp-microvolt-speed1 = <0xe09c0 0xe09c0 0x10c8e0>;
			opp-hz = <0x00 0x23c34600>;
			opp-microvolt-speed2 = <0xe09c0 0xe09c0 0x10c8e0>;
			opp-microvolt-speed0 = <0xdbba0 0xdbba0 0x10c8e0>;
			clock-latency-ns = <0x3b9b0>;
		};

		opp-1416000000 {
			opp-microvolt-speed1 = <0x10c8e0 0x10c8e0 0x10c8e0>;
			opp-hz = <0x00 0x54667200>;
			opp-microvolt-speed2 = <0x10c8e0 0x10c8e0 0x10c8e0>;
			opp-microvolt-speed0 = <0x10c8e0 0x10c8e0 0x10c8e0>;
			clock-latency-ns = <0x3b9b0>;
		};

		opp-1344000000 {
			opp-microvolt-speed1 = <0x10c8e0 0x10c8e0 0x10c8e0>;
			opp-hz = <0x00 0x501bd000>;
			opp-microvolt-speed2 = <0x10c8e0 0x10c8e0 0x10c8e0>;
			opp-microvolt-speed0 = <0x100590 0x100590 0x10c8e0>;
			clock-latency-ns = <0x3b9b0>;
		};
	};

	vcc33-wifi {
		regulator-max-microvolt = <0x325aa0>;
		regulator-always-on;
		regulator-min-microvolt = <0x325aa0>;
		regulator-name = "vcc33-wifi";
		compatible = "regulator-fixed";
		phandle = <0x20>;
		vin-supply = <0x52>;
	};

	aliases {
		ethernet0 = "/soc/ethernet@5030000";
		serial5 = "/soc/serial@5001400";
		serial3 = "/soc/serial@5000c00";
		serial4 = "/soc/serial@5001000";
		serial2 = "/soc/serial@5000800";
		serial0 = "/soc/serial@5000000";
	};

	display-engine {
		allwinner,pipelines = <0x05>;
		compatible = "allwinner,sun50i-h6-display-engine";
		status = "okay";
		phandle = <0x54>;
	};

	chosen {
		linux,initrd-end = <0x00 0x49fff4d9>;
		bootargs = "root=UUID=1eb12926-39f4-4c68-9f32-38360510d193 rootwait rootfstype=ext4 splash=verbose console=ttyS0,115200 console=tty1 consoleblank=0 loglevel=1 ubootpart=703fcbf5-01 usb-storage.quirks=   cgroup_enable=memory swapaccount=1";
		linux,initrd-start = <0x00 0x49430000>;
		stdout-path = "serial0:115200n8";
	};

	osc24M-clk {
		clock-output-names = "osc24M";
		#clock-cells = <0x00>;
		clock-frequency = <0x16e3600>;
		compatible = "fixed-clock";
		phandle = <0x0f>;
	};

	ac200_clk {
		#clock-cells = <0x00>;
		clock-frequency = <0x1e8480>;
		compatible = "pwm-clock";
		status = "okay";
		phandle = <0x32>;
		pwms = <0x53 0x05 0x1f4 0x00>;
	};

	vcc-wifi-io {
		regulator-max-microvolt = <0x1b7740>;
		regulator-always-on;
		regulator-min-microvolt = <0x1b7740>;
		regulator-name = "vcc-wifi-io";
		compatible = "regulator-fixed";
		phandle = <0x21>;
		vin-supply = <0x20>;
	};

	pmu {
		interrupt-affinity = <0x06 0x07 0x08 0x09>;
		interrupts = <0x00 0x8c 0x04 0x00 0x8d 0x04 0x00 0x8e 0x04 0x00 0x8f 0x04>;
		compatible = "arm,cortex-a53-pmu";
	};

	cpus {
		#address-cells = <0x01>;
		#size-cells = <0x00>;

		cpu@1 {
			clocks = <0x02 0x15>;
			device_type = "cpu";
			compatible = "arm,cortex-a53";
			reg = <0x01>;
			enable-method = "psci";
			phandle = <0x07>;
			operating-points-v2 = <0x03>;
			clock-latency-ns = <0x3b9b0>;
			#cooling-cells = <0x02>;
		};

		cpu@2 {
			clocks = <0x02 0x15>;
			device_type = "cpu";
			compatible = "arm,cortex-a53";
			reg = <0x02>;
			enable-method = "psci";
			phandle = <0x08>;
			operating-points-v2 = <0x03>;
			clock-latency-ns = <0x3b9b0>;
			#cooling-cells = <0x02>;
		};

		cpu@0 {
			cpu-supply = <0x04>;
			clocks = <0x02 0x15>;
			device_type = "cpu";
			compatible = "arm,cortex-a53";
			status = "okay";
			reg = <0x00>;
			enable-method = "psci";
			phandle = <0x06>;
			operating-points-v2 = <0x03>;
			clock-latency-ns = <0x3b9b0>;
			#cooling-cells = <0x02>;
		};

		cpu@3 {
			clocks = <0x02 0x15>;
			device_type = "cpu";
			compatible = "arm,cortex-a53";
			reg = <0x03>;
			enable-method = "psci";
			phandle = <0x09>;
			operating-points-v2 = <0x03>;
			clock-latency-ns = <0x3b9b0>;
			#cooling-cells = <0x02>;
		};
	};

	__symbols__ {
		pwm3_ph_pin = "/soc/pinctrl@300b000/pwm3-ph-pin";
		i2c3 = "/soc/i2c@5002c00";
		pwm = "/soc/pwm@300a000";
		syscon = "/soc/syscon@3000000";
		ohci2 = "/soc/usb@5310400";
		ths_calibration = "/soc/efuse@3006000/thermal-sensor-calibration@14";
		wifi_pwrseq = "/wifi-pwrseq";
		emac1 = "/soc/ethernet@5030000";
		pwm4_ph_pin = "/soc/pinctrl@300b000/pwm4-ph-pin";
		ahub_dam_plat = "/soc/ahub_dam_plat@5097000";
		ir = "/soc/ir@7040000";
		r_rsb_pins = "/soc/pinctrl@7022000/r-rsb-pins";
		i2c4_ph_pins = "/soc/pinctrl@300b000/i2c4-ph-pins";
		ephy_calibration = "/soc/efuse@3006000/ephy-calibration@2c";
		i2c1 = "/soc/i2c@5002400";
		r_i2c_pins = "/soc/pinctrl@7022000/r-i2c-pins";
		ohci0 = "/soc/usb@5101400";
		hdmi_con_in = "/connector/port/endpoint";
		display_clocks = "/soc/bus@1000000/clock@8000";
		gpu = "/soc/gpu@1800000";
		spi0 = "/soc/spi@5010000";
		pwm1_pi_pin = "/soc/pinctrl@300b000/pwm1-pi-pin";
		rmii_pins = "/soc/pinctrl@300b000/rmii-pins";
		pwm5 = "/soc/pwm5@0300a000";
		mmc1 = "/soc/mmc@4021000";
		r_ccu = "/soc/clock@7010000";
		hdmi_phy = "/soc/hdmi-phy@6010000";
		pwm2_pi_pin = "/soc/pinctrl@300b000/pwm2-pi-pin";
		i2c1_pi_pins = "/soc/pinctrl@300b000/i2c1-pi-pins";
		uart4 = "/soc/serial@5001000";
		tcon_top_hdmi_in = "/soc/tcon-top@6510000/ports/port@4";
		mmc2_pins = "/soc/pinctrl@300b000/mmc2-pins";
		pwm3_pi_pin = "/soc/pinctrl@300b000/pwm3-pi-pin";
		dma = "/soc/dma-controller@3002000";
		ddr_alert = "/thermal-zones/ddr-thermal/trips/ddr-alert";
		ccu = "/soc/clock@3001000";
		pwm3 = "/soc/pwm3@0300a000";
		tcon_tv = "/soc/lcd-controller@6515000";
		tcon_top_hdmi_out = "/soc/tcon-top@6510000/ports/port@5";
		pwm4_pi_pin = "/soc/pinctrl@300b000/pwm4-pi-pin";
		sram_a2 = "/soc/syscon@3000000/sram@100000";
		cpu3 = "/cpus/cpu@3";
		uart2 = "/soc/serial@5000800";
		ir_rx_pin = "/soc/pinctrl@300b000/ir-rx-pin";
		rmii_phy = "/soc/ethernet@5030000/mdio/ethernet-phy@1";
		tcon_top_mixer0_in = "/soc/tcon-top@6510000/ports/port@0";
		ahub1_mach = "/soc/ahub1_mach";
		gic = "/soc/interrupt-controller@3021000";
		i2c1_ph_pins = "/soc/pinctrl@300b000/i2c1-ph-pins";
		leds = "/leds";
		pwm1 = "/soc/pwm1@0300a000";
		uart3_pi_pins = "/soc/pinctrl@300b000/uart3-pi-pins";
		mmc1_pins = "/soc/pinctrl@300b000/mmc1-pins";
		ve_alert = "/thermal-zones/ve-thermal/trips/ve-alert";
		spi1_cs0_pin = "/soc/pinctrl@300b000/spi1-cs0-pin";
		ac200_ephy = "/soc/i2c@5002c00/mfd@10/phy";
		mdio1 = "/soc/ethernet@5030000/mdio";
		gpu_opp_table = "/gpu-opp-table";
		mixer0 = "/soc/bus@1000000/mixer@100000";
		cpu1 = "/cpus/cpu@1";
		scpi_sram = "/soc/syscon@3000000/sram@100000/scpi-sram@17c00";
		uart0 = "/soc/serial@5000000";
		ehci2 = "/soc/usb@5310000";
		uart1_ph_pins = "/soc/pinctrl@300b000/uart1-ph-pins";
		dump_reg = "/soc/dump_reg@20000";
		mixer0_out = "/soc/bus@1000000/mixer@100000/ports/port@1";
		r_rsb = "/soc/rsb@7083000";
		reg_dcdc2 = "/soc/i2c@7081400/pmic@36/regulators/dcdc2";
		i2c4 = "/soc/i2c@5003000";
		pwm5_pin = "/soc/pinctrl@300b000/pwm5-pin";
		ac200_x = "/soc/i2c@5002c00/mfd@10";
		ohci3 = "/soc/usb@5311400";
		addr_mgt = "/soc/addr-mgt";
		cpu_opp_table = "/opp-table-cpu";
		cpu_speed_grade = "/soc/efuse@3006000/cpu-speed-grade@00";
		i2c3_ph_pins = "/soc/pinctrl@300b000/i2c3-ph-pins";
		ehci0 = "/soc/usb@5101000";
		reg_vcc_wifi_io = "/vcc-wifi-io";
		hdmi_out = "/soc/hdmi@6000000/ports/port@1";
		tcon_top_hdmi_in_tcon_tv = "/soc/tcon-top@6510000/ports/port@4/endpoint@0";
		i2c2 = "/soc/i2c@5002800";
		tcon_top = "/soc/tcon-top@6510000";
		ohci1 = "/soc/usb@5200400";
		mmc0_pins = "/soc/pinctrl@300b000/mmc0-pins";
		sram_c = "/soc/syscon@3000000/sram@28000";
		emac0 = "/soc/ethernet@5020000";
		reg_dldo1 = "/soc/i2c@7081400/pmic@36/regulators/ldo2";
		spi1 = "/soc/spi@5011000";
		hdmi_out_con = "/soc/hdmi@6000000/ports/port@1/endpoint";
		usbphy = "/soc/phy@5100400";
		uart2_ph_rts_cts_pins = "/soc/pinctrl@300b000/uart2-ph-rts-cts-pins";
		i2c3_pa_pins = "/soc/pinctrl@300b000/i2c3-pa-pins";
		tcon_top_mixer0_out = "/soc/tcon-top@6510000/ports/port@1";
		ahub1_plat = "/soc/ahub1_plat";
		tcon_top_mixer0_out_tcon_tv = "/soc/tcon-top@6510000/ports/port@1/endpoint@2";
		de3_sram = "/soc/syscon@3000000/sram@28000/sram-section@0";
		i2c0 = "/soc/i2c@5002000";
		mmc2 = "/soc/mmc@4022000";
		ahub1_codec = "/soc/ahub1_mach/soundcard-mach,codec";
		spi1_pins = "/soc/pinctrl@300b000/spi1-pins";
		axp313a = "/soc/i2c@7081400/pmic@36";
		i2c0_pi_pins = "/soc/pinctrl@300b000/i2c0-pi-pins";
		cpu_alert = "/thermal-zones/cpu-thermal/trips/cpu-alert";
		spi1_cs1_pin = "/soc/pinctrl@300b000/spi1-cs1-pin";
		ahub1_cpu = "/soc/ahub1_mach/soundcard-mach,cpu";
		usbotg = "/soc/usb@5100000";
		i2s3_pins = "/soc/pinctrl@300b000/i2s3-pins";
		uart5 = "/soc/serial@5001400";
		uart5_ph_pins = "/soc/pinctrl@300b000/uart5-ph-pins";
		codec = "/soc/codec@05096000";
		osc24M = "/osc24M-clk";
		hdmi_in_tcon_top = "/soc/hdmi@6000000/ports/port@0/endpoint";
		reg_vcc5v = "/vcc5v";
		tcon_tv_in = "/soc/lcd-controller@6515000/ports/port@0";
		uart1_ph_rts_cts_pins = "/soc/pinctrl@300b000/uart1-ph-rts-cts-pins";
		pwm4 = "/soc/pwm4@0300a000";
		mmc0 = "/soc/mmc@4020000";
		ac200_pwm_clk = "/ac200_clk";
		tcon_top_mixer0_in_mixer0 = "/soc/tcon-top@6510000/ports/port@0/endpoint@0";
		tcon_tv_out_tcon_top = "/soc/lcd-controller@6515000/ports/port@1/endpoint@1";
		tcon_tv_out = "/soc/lcd-controller@6515000/ports/port@1";
		r_pio = "/soc/pinctrl@7022000";
		uart3 = "/soc/serial@5000c00";
		i2c2_pi_pins = "/soc/pinctrl@300b000/i2c2-pi-pins";
		tcon_top_hdmi_out_hdmi = "/soc/tcon-top@6510000/ports/port@5/endpoint";
		sram_c1 = "/soc/syscon@3000000/sram@1a00000";
		spi0_pins = "/soc/pinctrl@300b000/spi0-pins";
		ahub_dam_mach = "/soc/ahub_dam_mach";
		reg_aldo1 = "/soc/i2c@7081400/pmic@36/regulators/ldo1";
		mixer0_out_tcon_top_mixer0 = "/soc/bus@1000000/mixer@100000/ports/port@1/endpoint";
		tcon_tv_in_tcon_top_mixer0 = "/soc/lcd-controller@6515000/ports/port@0/endpoint";
		uart2_pi_pins = "/soc/pinctrl@300b000/uart2-pi-pins";
		pwm2 = "/soc/pwm2@0300a000";
		spi0_cs0_pin = "/soc/pinctrl@300b000/spi0-cs0-pin";
		ve_sram = "/soc/syscon@3000000/sram@1a00000/sram-section@0";
		pio = "/soc/pinctrl@300b000";
		reg_vcc33_wifi = "/vcc33-wifi";
		uart0_ph_pins = "/soc/pinctrl@300b000/uart0-ph-pins";
		cpu2 = "/cpus/cpu@2";
		ths = "/soc/thermal-sensor@5070400";
		uart1 = "/soc/serial@5000400";
		ehci3 = "/soc/usb@5311000";
		hdmi = "/soc/hdmi@6000000";
		r_i2c = "/soc/i2c@7081400";
		hdmi_in = "/soc/hdmi@6000000/ports/port@0";
		pwm1_ph_pin = "/soc/pinctrl@300b000/pwm1-ph-pin";
		reg_dcdc3 = "/soc/i2c@7081400/pmic@36/regulators/dcdc3";
		ext_rgmii_pins = "/soc/pinctrl@300b000/rgmii-pins";
		de = "/display-engine";
		gpu_alert = "/thermal-zones/gpu-thermal/trips/gpu-alert";
		pwm0 = "/soc/pwm0@0300a000";
		i2c2_ph_pins = "/soc/pinctrl@300b000/i2c2-ph-pins";
		pwm2_ph_pin = "/soc/pinctrl@300b000/pwm2-ph-pin";
		rtc = "/soc/rtc@7000000";
		watchdog = "/soc/watchdog@30090a0";
		mdio0 = "/soc/ethernet@5020000/mdio";
		uart4_pi_pins = "/soc/pinctrl@300b000/uart4-pi-pins";
		cpu0 = "/cpus/cpu@0";
		sid = "/soc/efuse@3006000";
		ehci1 = "/soc/usb@5200000";
		r_lradc = "/soc/lradc@5070800";
		reg_dcdc1 = "/soc/i2c@7081400/pmic@36/regulators/dcdc1";
		uart2_ph_pins = "/soc/pinctrl@300b000/uart2-ph-pins";
	};

	reserved-memory {
		#address-cells = <0x02>;
		#size-cells = <0x02>;
		ranges;

		secmon@40000000 {
			reg = <0x00 0x40000000 0x00 0x80000>;
			no-map;
		};
	};

	memory {
		device_type = "memory";
		reg = <0x00 0x40000000 0x00 0x80000000>;
	};
};
